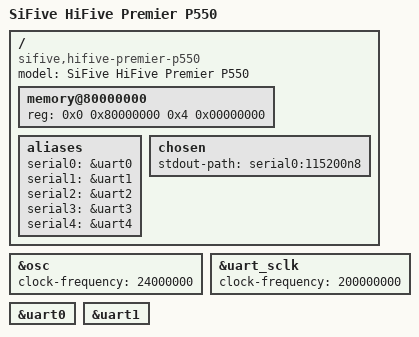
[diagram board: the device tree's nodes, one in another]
// SPDX-License-Identifier: (GPL-2.0 OR MIT)
/*
 * Copyright (C) 2024 Inochi Amaoto <inochiama@outlook.com>
 */

/dts-v1/;

#include "eic7700.dtsi"

/ {
	compatible = "sifive,hifive-premier-p550", "eswin,eic7700";
	model = "SiFive HiFive Premier P550";

	memory@80000000 {
		device_type = "memory";
		reg = <0x0 0x80000000 0x4 0x00000000>;
	};

	aliases {
		serial0 = &uart0;
		serial1 = &uart1;
		serial2 = &uart2;
		serial3 = &uart3;
		serial4 = &uart4;
	};

	chosen {
		stdout-path = "serial0:115200n8";
	};
};

&osc {
	clock-frequency = <24000000>;
};

&uart_sclk {
	clock-frequency = <200000000>;
};

&uart0 {
	status = "okay";
};

&uart1 {
	status = "okay";
};
